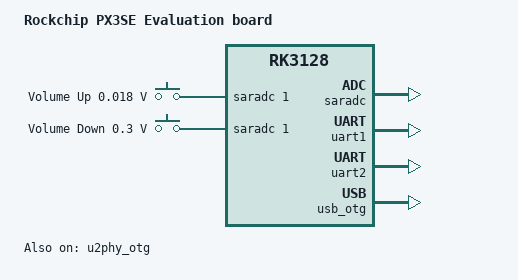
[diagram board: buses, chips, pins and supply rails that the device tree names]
/*
 * (C) Copyright 2018 Rockchip Electronics Co., Ltd
 *
 * SPDX-License-Identifier:     GPL-2.0+
 */

/dts-v1/;

#include <dt-bindings/input/input.h>
#include "rk3128.dtsi"
#include "rk3128-u-boot.dtsi"

/ {
	model = "Rockchip PX3SE Evaluation board";
	compatible = "rockchip,px3se-evb", "rockchip,px3se";

	adc-keys {
		compatible = "adc-keys";
		io-channels = <&saradc 1>;
		io-channel-names = "buttons";
		poll-interval = <100>;
		keyup-threshold-microvolt = <1800000>;

		vol-up {
			label = "Volume Up";
			linux,code = <KEY_VOLUMEUP>;
			press-threshold-microvolt = <18000>;
		};

		vol-down {
			label = "Volume Down";
			linux,code = <KEY_VOLUMEDOWN>;
			press-threshold-microvolt = <300000>;
		};
	};

	chosen {
		stdout-path = &uart1;
	};
};

&emmc {
	fifo-mode;
	status = "disabled";
};

&nandc {
	status = "disabled";
};

&saradc {
	status = "okay";
};

&u2phy_otg {
	status = "okay";
};

&uart1 {
	clock-frequency = <24000000>;
	u-boot,dm-pre-reloc;
	status = "okay";
};

&uart2 {
	status = "okay";
};

&usb_otg {
	status = "okay";
};
